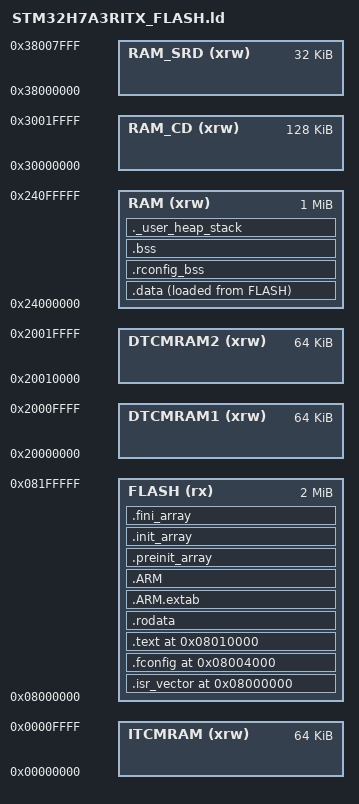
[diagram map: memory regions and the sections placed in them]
/*
******************************************************************************
**
**  File        : LinkerScript.ld
**
**  Author      : STM32CubeIDE
**
**  Abstract    : Linker script for STM32H7 series
**                2048Kbytes FLASH and 1376Kbytes RAM
**
**                Set heap size, stack size and stack location according
**                to application requirements.
**
**                Set memory bank area and size if external memory is used.
**
**  Target      : STMicroelectronics STM32
**
**  Distribution: The file is distributed as is, without any warranty
**                of any kind.
**
*****************************************************************************
** @attention
**
** Copyright (c) 2022 STMicroelectronics.
** All rights reserved.
**
** This software is licensed under terms that can be found in the LICENSE file
** in the root directory of this software component.
** If no LICENSE file comes with this software, it is provided AS-IS.
**
****************************************************************************
*/

/* Entry Point */
ENTRY(Reset_Handler)

/* Highest address of the user mode stack */
_estack = ORIGIN(RAM) + LENGTH(RAM);    /* end of RAM */
/* Generate a link error if heap and stack don't fit into RAM */
_Min_Heap_Size = 0x600 ;      /* required amount of heap  */
_Min_Stack_Size = 0x600 ; /* required amount of stack */

/* Specify the memory areas */
MEMORY
{
  ITCMRAM (xrw)  : ORIGIN = 0x00000000, LENGTH = 64K
  FLASH (rx)     : ORIGIN = 0x08000000, LENGTH = 2048K
  DTCMRAM1 (xrw) : ORIGIN = 0x20000000, LENGTH = 64K
  DTCMRAM2 (xrw) : ORIGIN = 0x20010000, LENGTH = 64K
  RAM (xrw)      : ORIGIN = 0x24000000, LENGTH = 1024K
  RAM_CD (xrw)   : ORIGIN = 0x30000000, LENGTH = 128K
  RAM_SRD (xrw)  : ORIGIN = 0x38000000, LENGTH = 32K
}

/* Define output sections */
SECTIONS
{
  /* The startup code goes first into FLASH */
  .isr_vector (0x08000000) :
  {
    . = ALIGN(4);
    KEEP(*(.isr_vector)) /* Startup code */
    . = ALIGN(4);
  } >FLASH

 .fconfig (0x08004000) :
  {
    . = ALIGN(4);
    __fconfig_start = .;  /* create symbol for start of the FConfig section */
    KEEP(*(.fconfig))
    __fconfig_end   = .;  /* create symbol for end of the FConfig section */
    . = ALIGN(4);
  } >FLASH


  /* The program code and other data goes into FLASH */
  /* The .text address is changed to 0x08010000 the configuration address was clasing with .text addresses*/
  .text (0x08010000) :
  {
    . = ALIGN(4);
    __dw_drivers_start = .;
    *(.dw_drivers)
    __dw_drivers_end = .;

    . = ALIGN(4);
    __known_commands_start = .;
    KEEP(*(.known_commands_anytime))
    __known_commands_app_start = .;
    KEEP(*(.known_commands_app))
    __known_app_subcommands_start = .;
    KEEP(*(.known_app_subcommands))
    __known_commands_ilde_start = .;
    KEEP(*(.known_commands_ilde))
    __known_commands_service_start = .;
    KEEP(*(.known_commands_service))
    __known_commands_end = .;

    . = ALIGN(4);
    __known_apps_start = .;
    KEEP(*(.known_apps))
    __known_apps_end = .;

    __config_entry_start = .;
    KEEP(*(.config_entry))
    __config_entry_end = .;

    . = ALIGN(4);
    *(.text)           /* .text sections (code) */
    *(.text*)          /* .text* sections (code) */
    *(.glue_7)         /* glue arm to thumb code */
    *(.glue_7t)        /* glue thumb to arm code */
    *(.eh_frame)

    KEEP (*(.init))
    KEEP (*(.fini))
    
    . = ALIGN(4);
    _etext = .;        /* define a global symbols at end of code */
  } >FLASH

  /* Constant data goes into FLASH */
  .rodata :
  {
    . = ALIGN(4);
    *(.rodata)         /* .rodata sections (constants, strings, etc.) */
    *(.rodata*)        /* .rodata* sections (constants, strings, etc.) */
    . = ALIGN(4);
  } >FLASH

  .ARM.extab   : { *(.ARM.extab* .gnu.linkonce.armextab.*) } >FLASH
  .ARM : {
    __exidx_start = .;
    *(.ARM.exidx*)
    __exidx_end = .;
  } >FLASH

  .preinit_array     :
  {
    PROVIDE_HIDDEN (__preinit_array_start = .);
    KEEP (*(.preinit_array*))
    PROVIDE_HIDDEN (__preinit_array_end = .);
  } >FLASH
  .init_array :
  {
    PROVIDE_HIDDEN (__init_array_start = .);
    KEEP (*(SORT(.init_array.*)))
    KEEP (*(.init_array*))
    PROVIDE_HIDDEN (__init_array_end = .);
  } >FLASH
  .fini_array :
  {
    PROVIDE_HIDDEN (__fini_array_start = .);
    KEEP (*(SORT(.fini_array.*)))
    KEEP (*(.fini_array*))
    PROVIDE_HIDDEN (__fini_array_end = .);
  } >FLASH

  /* used by the startup to initialize data */
  _sidata = LOADADDR(.data);

  /* Initialized data sections goes into RAM, load LMA copy after code */
  .data :
  {
    . = ALIGN(4);
    _sdata = .;        /* create a global symbol at data start */
    *(.data)           /* .data sections */
    *(.data*)          /* .data* sections */

    . = ALIGN(4);
    _edata = .;        /* define a global symbol at data end */
  } >RAM AT> FLASH

  .rconfig_bss :
  {
      . = ALIGN(4);
      __rconfig_start = .;
      KEEP(*(.rconfig))
      . = ALIGN(4);
      __rconfig_end = .;
      KEEP(*(.rconfig_crc))
      __rconfig_crc_end = .;
  } > RAM

  /* Uninitialized data section */
  . = ALIGN(4);
  .bss :
  {
    /* This is used by the startup in order to initialize the .bss section */
    _sbss = .;         /* define a global symbol at bss start */
    __bss_start__ = _sbss;
    *(.bss)
    *(.bss*)
    *(COMMON)

    . = ALIGN(4);
    _ebss = .;         /* define a global symbol at bss end */
    __bss_end__ = _ebss;
  } >RAM

  /* User_heap_stack section, used to check that there is enough RAM left */
  ._user_heap_stack :
  {
    . = ALIGN(8);
    PROVIDE ( end = . );
    PROVIDE ( _end = . );
    PROVIDE ( __end__ = . );
    . = . + _Min_Heap_Size;
    . = . + _Min_Stack_Size;
    . = ALIGN(8);
  } >RAM

  /* Remove information from the standard libraries */
  /DISCARD/ :
  {
    libc.a ( * )
    libm.a ( * )
    libgcc.a ( * )
  }

  .ARM.attributes 0 : { *(.ARM.attributes) }
}


